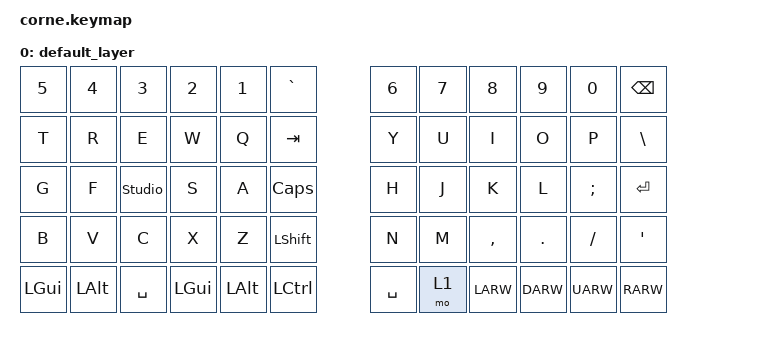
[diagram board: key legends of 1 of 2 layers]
#include <behaviors.dtsi>
#include <dt-bindings/zmk/keys.h>
#include <dt-bindings/zmk/bt.h>

/ {
        keymap {
                compatible = "zmk,keymap";

                default_layer {
// ---------------------------------------------------------------------------------
// |   `  |  1  |  2  |  3  |  4  |  5  |     |  6  |  7  |  8  |  9  |  0  | BKSP |
// |  TAB |  Q  |  W  |  E  |  R  |  T  |     |  Y  |  U  |  I  |  O  |  P  |  \   |
// | CAPS |  A  |  S  |  D  |  F  |  G  |     |  H  |  J  |  K  |  L  |  ;  |  ENT |
// | SHFT |  Z  |  X  |  C  |  V  |  B  |     |  N  |  M  |  ,  |  .  |  /  | APOS |
// | CTRL | ALT | GUI | SPC | SPC | SPC |     | SPC | LOW |LARW |DARW |UARW | RARW |
                        bindings = <
   &kp N5    &kp N4    &kp N3     &kp N2    &kp N1    &kp GRAVE             &kp N6     &kp N7  &kp N8     &kp N9    &kp N0    &kp BSPC
   &kp T     &kp R     &kp E      &kp W     &kp Q     &kp TAB               &kp Y      &kp U   &kp I      &kp O     &kp P     &kp BSLH
   &kp G     &kp F     &studio_unlock      &kp S     &kp A     &kp CAPS              &kp H      &kp J   &kp K      &kp L     &kp SEMI  &kp RET
   &kp B     &kp V     &kp C      &kp X     &kp Z     &kp LSHFT             &kp N      &kp M   &kp COMMA  &kp DOT   &kp FSLH  &kp APOS
   &kp LGUI  &kp LALT  &kp SPACE  &kp LGUI  &kp LALT  &kp LCTRL             &kp SPACE  &mo 1   &kp LARW   &kp DARW  &kp UARW  &kp RARW
                        >;
                };
                lower_layer {
// ------------------------------------------------------------------------------------------------------------
// |       |  BT1  |  BT2  |  BT3  |  BT4  |  BT5  |          |       |       |       |       |       | BTCLR |
// |       |       |       |       |       |       |          |       |       |       |       |       |       |
// |       |       |       | LPAR  | RPAR  |       |          |       | LBKT  | RBKT  |       |       |       |
// |       |       |       |       |       |       |          |       |       |       |       |       |       |
                        bindings = <
   &trans    &bt BT_SEL 0   &bt BT_SEL 1   &bt BT_SEL 2   &bt BT_SEL 3   &bt BT_SEL 4           &trans    &trans    &trans   &trans   &trans  &bt BT_CLR
   &trans    &trans         &trans         &trans         &trans         &trans                 &trans    &trans    &trans   &trans   &trans  &trans
   &trans    &trans         &trans         &kp LPAR       &kp RPAR       &trans                 &trans    &kp LBKT  &kp RBKT &kp MINUS   &kp EQUAL  &trans
   &trans    &trans         &trans         &trans         &trans         &trans                 &trans    &trans    &trans   &trans   &trans  &trans
                        >;
                };
        };
};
